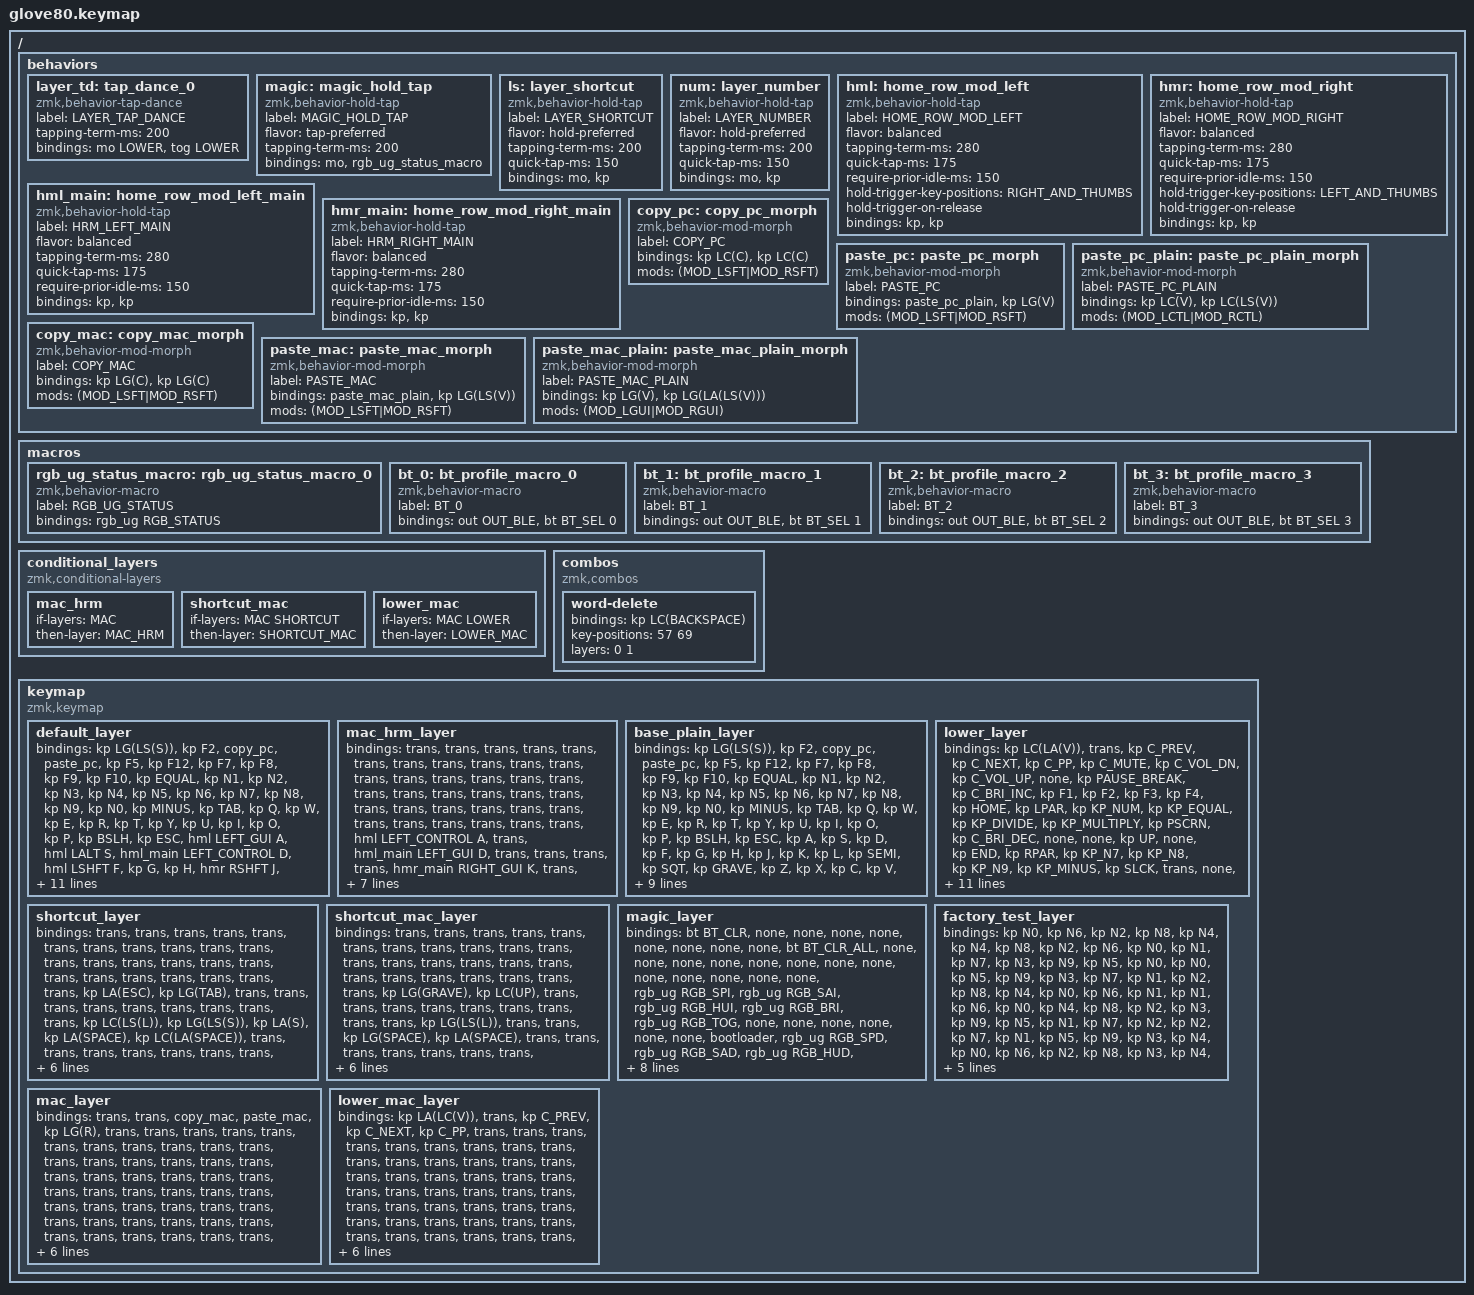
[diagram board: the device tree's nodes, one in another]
/*
 * Copyright (c) 2020 The ZMK Contributors
 *
 * SPDX-License-Identifier: MIT
 */

#include <behaviors.dtsi>
#include <dt-bindings/zmk/bt.h>
#include <dt-bindings/zmk/keys.h>
#include <dt-bindings/zmk/outputs.h>
#include <dt-bindings/zmk/rgb.h>

#define HYPER LC(LS(LG(LALT)))

// ---------------------------------------------------------------------------
// LAYERS
//   0 DEFAULT       base + home row mods. PC/Windows native.
//   1 BASE_PLAIN    same base, home row mods DISABLED (plain letters)
//   2 LOWER         numbers / media / nav  (+ Enter, Backspace, F1-F4)
//   3 SHORTCUT      left-hand shortcut cluster (PC)    -- HOLD left thumb
//   4 SHORTCUT_MAC  left-hand shortcut cluster (Mac)   -- auto when MAC mode on
//   5 MAGIC         BT / RGB / reset + OS & HRM toggles
//   6 FACTORY_TEST  factory test
//   7 MAC           OS flag: while ON, the base layer emits Cmd instead of Ctrl
//   8 LOWER_MAC     Mac variants of the LOWER layer (auto when MAC + LOWER)
//
// TOGGLES (all live on the MAGIC layer, right home row):
//   K = &tog BASE_PLAIN  -> home row mods off / on
//   L = &tog MAC         -> flip PC <-> Mac
//
// NOTE ON OS MODE: ZMK cannot persist layer state across a power cycle, so
// whichever OS is the BASE layer is what you get on boot. The base is PC, so
// Windows works with zero setup; Mac needs MAGIC+L after the board powers on.
//
// IMPORTANT: never use &to on this keymap. ZMK's `to` behavior deactivates
// every layer above its target, which silently wipes the MAC flag (layer 7).
// That is why the HRM toggle and the LOWER lock-exit both use &tog instead.
// ---------------------------------------------------------------------------

#define DEFAULT      0
#define MAC_HRM      1
#define BASE_PLAIN   2
#define LOWER        3
#define SHORTCUT     4
#define SHORTCUT_MAC 5
#define MAGIC        6
#define FACTORY_TEST 7
#define MAC          8
#define LOWER_MAC    9

// Positions of one hand + both thumb clusters, used to make the home row mods
// "positional" (a mod only triggers when combined with a key on the OTHER
// side of the board, so fast same-hand rolls never accidentally hold a mod).
// Right-hand keys + all thumbs  -> allowed triggers for LEFT home row mods

#define RIGHT_AND_THUMBS  5 6 7 8 9 16 17 18 19 20 21 28 29 30 31 32 33 40 41 42 43 44 45 58 59 60 61 62 63 75 76 77 78 79 52 53 54 55 56 57 69 70 71 72 73 74

// Left-hand keys + all thumbs   -> allowed triggers for RIGHT home row mods

#define LEFT_AND_THUMBS   0 1 2 3 4 10 11 12 13 14 15 22 23 24 25 26 27 34 35 36 37 38 39 46 47 48 49 50 51 64 65 66 67 68 52 53 54 55 56 57 69 70 71 72 73 74

/ {
    behaviors {
        // For the "layer" key, it'd nice to be able to use it as either a shift or a toggle.
        // Configure it as a tap dance, so the first tap (or hold) is a &mo and the second tap is a &tog.
        // (&tog, not &to -- see the IMPORTANT note at the top of the file.)

        layer_td: tap_dance_0 {
            compatible = "zmk,behavior-tap-dance";
            label = "LAYER_TAP_DANCE";
            #binding-cells = <0>;
            tapping-term-ms = <200>;
            bindings = <&mo LOWER>, <&tog LOWER>;
        };

        magic: magic_hold_tap {
            compatible = "zmk,behavior-hold-tap";
            label = "MAGIC_HOLD_TAP";
            #binding-cells = <2>;
            flavor = "tap-preferred";
            tapping-term-ms = <200>;
            bindings = <&mo>, <&rgb_ug_status_macro>;
        };

        // Left thumb: tap = Delete, hold = SHORTCUT layer (left-hand shortcuts).

        ls: layer_shortcut {
            compatible = "zmk,behavior-hold-tap";
            label = "LAYER_SHORTCUT";
            #binding-cells = <2>;
            flavor = "hold-preferred";
            tapping-term-ms = <200>;
            quick-tap-ms = <150>;
            bindings = <&mo>, <&kp>;
        };

        // Right thumb: tap = Left Alt, hold = LOWER (number/nav) layer. Lets the
        // whole number layer be reached with the right hand alone. Hold-preferred
        // so numbers register immediately while the thumb is held.

        num: layer_number {
            compatible = "zmk,behavior-hold-tap";
            label = "LAYER_NUMBER";
            #binding-cells = <2>;
            flavor = "hold-preferred";
            tapping-term-ms = <200>;
            quick-tap-ms = <150>;
            bindings = <&mo>, <&kp>;
        };

        // Home row mods, left hand. "balanced" flavor + positional trigger +
        // require-prior-idle gives the "glorious/timeless" feel: taps stay taps
        // while typing, holds only engage when paired with the other hand.

        hml: home_row_mod_left {
            compatible = "zmk,behavior-hold-tap";
            label = "HOME_ROW_MOD_LEFT";
            #binding-cells = <2>;
            flavor = "balanced";
            tapping-term-ms = <280>;
            quick-tap-ms = <175>;
            require-prior-idle-ms = <150>;
            hold-trigger-key-positions = <RIGHT_AND_THUMBS>;
            hold-trigger-on-release;
            bindings = <&kp>, <&kp>;
        };

        // Home row mods, right hand.

        hmr: home_row_mod_right {
            compatible = "zmk,behavior-hold-tap";
            label = "HOME_ROW_MOD_RIGHT";
            #binding-cells = <2>;
            flavor = "balanced";
            tapping-term-ms = <280>;
            quick-tap-ms = <175>;
            require-prior-idle-ms = <150>;
            hold-trigger-key-positions = <LEFT_AND_THUMBS>;
            hold-trigger-on-release;
            bindings = <&kp>, <&kp>;
        };

        // "Main shortcut modifier" home row mods (D and K) -- deliberately NOT
        // positional. They hold Ctrl on PC and Cmd on Mac (MAC_HRM layer swaps
        // them), matching how the thumb Ctrl/Cmd keys swap.
        //
        // Most shortcuts are that modifier + a key on the SAME hand (C/V/X/Z/S/W/T
        // all live under the left hand). The positional variants above cancel the
        // hold in exactly that case, so dropping hold-trigger-key-positions here
        // lets one-handed Ctrl+C / Cmd+C work.
        //
        // require-prior-idle-ms keeps this safe: mid-word a hold is refused
        // outright, so rolls like "de"/"ed" still type letters. If you ever get a
        // stray Ctrl/Cmd while typing, raise require-prior-idle-ms toward 200.

        hml_main: home_row_mod_left_main {
            compatible = "zmk,behavior-hold-tap";
            label = "HRM_LEFT_MAIN";
            #binding-cells = <2>;
            flavor = "balanced";
            tapping-term-ms = <280>;
            quick-tap-ms = <175>;
            require-prior-idle-ms = <150>;
            bindings = <&kp>, <&kp>;
        };

        hmr_main: home_row_mod_right_main {
            compatible = "zmk,behavior-hold-tap";
            label = "HRM_RIGHT_MAIN";
            #binding-cells = <2>;
            flavor = "balanced";
            tapping-term-ms = <280>;
            quick-tap-ms = <175>;
            require-prior-idle-ms = <150>;
            bindings = <&kp>, <&kp>;
        };

        // Copy / paste with Shift masked. Tap = copy / paste. Shift + PASTE
        // opens clipboard history: Win+V on PC, Cmd+Shift+V on Mac.
        // Main modifier + PASTE pastes as plain text: Ctrl on PC, Cmd on Mac
        // (left thumb key next to the letters, or the D/K home-row hold).
        // Holding Shift on the copy key stays a plain copy (Shift is discarded
        // by mod-morph so it never leaks into Ctrl/Cmd+Shift+C).

        copy_pc: copy_pc_morph {
            compatible = "zmk,behavior-mod-morph";
            label = "COPY_PC";
            #binding-cells = <0>;
            bindings = <&kp LC(C)>, <&kp LC(C)>;

            mods = <(MOD_LSFT|MOD_RSFT)>;
        };

        paste_pc: paste_pc_morph {
            compatible = "zmk,behavior-mod-morph";
            label = "PASTE_PC";
            #binding-cells = <0>;
            bindings = <&paste_pc_plain>, <&kp LG(V)>;

            mods = <(MOD_LSFT|MOD_RSFT)>;
        };

        // Ctrl held (masked) -> Ctrl+Shift+V, plain-text paste on Windows.
        paste_pc_plain: paste_pc_plain_morph {
            compatible = "zmk,behavior-mod-morph";
            label = "PASTE_PC_PLAIN";
            #binding-cells = <0>;
            bindings = <&kp LC(V)>, <&kp LC(LS(V))>;

            mods = <(MOD_LCTL|MOD_RCTL)>;
        };

        copy_mac: copy_mac_morph {
            compatible = "zmk,behavior-mod-morph";
            label = "COPY_MAC";
            #binding-cells = <0>;
            bindings = <&kp LG(C)>, <&kp LG(C)>;

            mods = <(MOD_LSFT|MOD_RSFT)>;
        };

        paste_mac: paste_mac_morph {
            compatible = "zmk,behavior-mod-morph";
            label = "PASTE_MAC";
            #binding-cells = <0>;
            bindings = <&paste_mac_plain>, <&kp LG(LS(V))>;

            mods = <(MOD_LSFT|MOD_RSFT)>;
        };

        // Cmd held (masked) -> Option+Shift+Cmd+V, macOS "Paste and Match Style".
        paste_mac_plain: paste_mac_plain_morph {
            compatible = "zmk,behavior-mod-morph";
            label = "PASTE_MAC_PLAIN";
            #binding-cells = <0>;
            bindings = <&kp LG(V)>, <&kp LG(LA(LS(V)))>;

            mods = <(MOD_LGUI|MOD_RGUI)>;
        };
    };

    macros {
        rgb_ug_status_macro: rgb_ug_status_macro_0 {
            label = "RGB_UG_STATUS";
            compatible = "zmk,behavior-macro";
            #binding-cells = <0>;
            bindings = <&rgb_ug RGB_STATUS>;
        };

        bt_0: bt_profile_macro_0 {
            label = "BT_0";
            compatible = "zmk,behavior-macro";
            #binding-cells = <0>;
            bindings = <&out OUT_BLE &bt BT_SEL 0>;
        };

        bt_1: bt_profile_macro_1 {
            label = "BT_1";
            compatible = "zmk,behavior-macro";
            #binding-cells = <0>;
            bindings = <&out OUT_BLE &bt BT_SEL 1>;
        };

        bt_2: bt_profile_macro_2 {
            label = "BT_2";
            compatible = "zmk,behavior-macro";
            #binding-cells = <0>;
            bindings = <&out OUT_BLE &bt BT_SEL 2>;
        };

        bt_3: bt_profile_macro_3 {
            label = "BT_3";
            compatible = "zmk,behavior-macro";
            #binding-cells = <0>;
            bindings = <&out OUT_BLE &bt BT_SEL 3>;
        };
    };

    // While MAC mode (layer 7) AND the SHORTCUT layer (3) are both active, jump
    // to SHORTCUT_MAC (4) so the shortcut cluster emits macOS variants. Keys
    // that are identical on both OSes stay &trans there and fall through to 3.

    conditional_layers {
        compatible = "zmk,conditional-layers";

        // MAC mode swaps the home-row holds back to the Mac layout.
        mac_hrm {
            if-layers = <MAC>;
            then-layer = <MAC_HRM>;
        };

        shortcut_mac {
            if-layers = <MAC SHORTCUT>;
            then-layer = <SHORTCUT_MAC>;
        };

        // While MAC mode (7) AND the LOWER layer (2) are both active, jump to
        // LOWER_MAC (8). Needed because the MAC flag layer sits ABOVE LOWER and
        // would otherwise shadow the media keys, the right-thumb Backspace and
        // the desktop-switch arrows whenever Mac mode is on.

        lower_mac {
            if-layers = <MAC LOWER>;
            then-layer = <LOWER_MAC>;
        };
    };

    combos {
        compatible = "zmk,combos";

        // Delete previous word, via both thumbs. PC uses Ctrl+Backspace.
        //
        // Combos invoke a behavior directly rather than resolving through the
        // keymap, and a combo is live whenever ANY listed layer is active --
        // layer 0 always is -- so this cannot be made to follow the MAC toggle.
        // It is therefore PC-only. For the OS-aware version use the right thumb
        // LOWER key + left thumb Backspace, which is branched properly on the
        // LOWER / LOWER_MAC layers below.

        word-delete {
            bindings = <&kp LC(BACKSPACE)>;
            key-positions = <57 69>;
            layers = <0 1>;
        };
    };

    keymap {
        compatible = "zmk,keymap";

        default_layer {
            // ---------------------------------------------------------------------------------------------------------------------------------
            // | SNIP  |  F2 | COPY | PASTE|  F5  |                                                               |  F12  |  F7   |  F8  |   F9  |  F10 |
            // |  =    |  1  |  2  |  3   |  4   |  5   |                                                 |  6   |   7   |   8   |  9   |   0   |   -  |
            // |  TAB  |  Q  |  W  |  E   |  R   |  T   |                                                 |  Y   |   U   |   I   |  O   |   P   |   \  |
            // |  ESC  | A/W | S/A | D/C  | F/S  |  G   |                                                 |  H   |  J/S  |  K/C  | L/A  |  ;/W  |   '  |
            // |   `   |  Z  |  X  |  C   |  V   |  B   | LCTRL | DEL/SC| LOWER | | LGUI  | RET   | RCTRL |  N   |   M   |   ,   |  .   |   /   | PGUP |
            // | MAGIC | HOME| END | LEFT | RIGHT|      | LSHFT | BSPC  | LALT  | | ALT/L | SPACE | RSHFT |      |  UP   | DOWN  |  [   |   ]   | PGDN |
            //  ( home row mods: A=Win S=Alt D=Ctrl F=Shift  /  J=Shift K=Ctrl L=Alt ;=Win )
            //  ( same positions as the Mac: Mac Cmd -> PC Ctrl, Mac Ctrl -> PC Win, like the thumbs )
            //  ( SNIP = Win+Shift+S, same keycode as Cmd+Shift+S on Mac )
            //  ( COPY=Ctrl+C  PASTE=Ctrl+V (Shift+PASTE=Win+V history, Ctrl+PASTE=plain text)  /  DEL/SC = tap Delete, hold left-hand SHORTCUT layer )
            //  ( Ctrl also lives on the LEFT THUMB so Ctrl+A / Ctrl+C never need a same-hand stretch )

            bindings = <
&kp LG(LS(S))   &kp F2                   &copy_pc     &paste_pc        &kp F5                                                                                                                      &kp F12       &kp F7            &kp F8       &kp F9                       &kp F10
&kp EQUAL       &kp N1                   &kp N2       &kp N3           &kp N4        &kp N5                                                                                                &kp N6  &kp N7        &kp N8            &kp N9       &kp N0                       &kp MINUS
&kp TAB         &kp Q                    &kp W        &kp E            &kp R         &kp T                                                                                                 &kp Y   &kp U         &kp I             &kp O        &kp P                        &kp BSLH
&kp ESC         &hml LEFT_GUI A           &hml LALT S  &hml_main LEFT_CONTROL D  &hml LSHFT F  &kp G                                                                                                 &kp H   &hmr RSHFT J  &hmr_main RIGHT_CONTROL K  &hmr RALT L  &hmr RIGHT_GUI SEMI  &kp SQT
&kp GRAVE       &kp Z                    &kp X        &kp C            &kp V         &kp B   &kp LEFT_CONTROL  &ls SHORTCUT DEL  &layer_td  &kp LEFT_GUI         &kp ENTER  &kp RIGHT_CONTROL      &kp N   &kp M         &kp COMMA         &kp DOT      &kp FSLH                     &kp PG_UP
&magic MAGIC 0  &kp HOME                 &kp END      &kp LEFT         &kp RIGHT             &kp LEFT_SHIFT    &kp BACKSPACE     &kp LALT   &num LOWER LEFT_ALT  &kp SPACE  &kp RIGHT_SHIFT        &kp UP        &kp DOWN          &kp LBKT     &kp RBKT                     &kp PG_DN
            >;
        };

        mac_hrm_layer {
            // Active automatically while MAC is on (conditional layer).
            // Mac home-row holds: A=Ctrl D=Cmd / K=Cmd ;=Ctrl (S/L Alt, F/J Shift unchanged).
            // Sits BELOW BASE_PLAIN, LOWER and SHORTCUT so it never overrides them.

            bindings = <
&trans  &trans  &trans  &trans  &trans  &trans  &trans  &trans  &trans  &trans
&trans  &trans  &trans  &trans  &trans  &trans  &trans  &trans  &trans  &trans  &trans  &trans
&trans  &trans  &trans  &trans  &trans  &trans  &trans  &trans  &trans  &trans  &trans  &trans
&trans  &hml LEFT_CONTROL A  &trans  &hml_main LEFT_GUI D  &trans  &trans  &trans  &trans  &hmr_main RIGHT_GUI K  &trans  &hmr RIGHT_CONTROL SEMI  &trans
&trans  &trans  &trans  &trans  &trans  &trans  &trans  &trans  &trans  &trans  &trans  &trans  &trans  &trans  &trans  &trans  &trans  &trans
&trans  &trans  &trans  &trans  &trans  &trans  &trans  &trans  &trans  &trans  &trans  &trans  &trans  &trans  &trans  &trans
            >;
        };

        base_plain_layer {
            // Identical to DEFAULT but with home row mods disabled (plain A S D F / J K L ;).
            // Reach via MAGIC + K (&tog BASE_PLAIN); press again to turn home row mods back on.
            // Thumb cluster must mirror DEFAULT exactly, or the MAC layer's overrides land
            // on the wrong keys when both are active.

            bindings = <
&kp LG(LS(S))   &kp F2    &copy_pc  &paste_pc  &kp F5                                                                                                                  &kp F12  &kp F7     &kp F8    &kp F9    &kp F10
&kp EQUAL       &kp N1    &kp N2    &kp N3     &kp N4  &kp N5                                                                                                  &kp N6  &kp N7   &kp N8     &kp N9    &kp N0    &kp MINUS
&kp TAB         &kp Q     &kp W     &kp E      &kp R   &kp T                                                                                                   &kp Y   &kp U    &kp I      &kp O     &kp P     &kp BSLH
&kp ESC         &kp A     &kp S     &kp D      &kp F   &kp G                                                                                                   &kp H   &kp J    &kp K      &kp L     &kp SEMI  &kp SQT
&kp GRAVE       &kp Z     &kp X     &kp C      &kp V   &kp B   &kp LEFT_CONTROL  &ls SHORTCUT DEL  &layer_td  &kp LEFT_GUI         &kp ENTER  &kp RIGHT_CONTROL  &kp N   &kp M    &kp COMMA  &kp DOT   &kp FSLH  &kp PG_UP
&magic MAGIC 0  &kp HOME  &kp END   &kp LEFT   &kp RIGHT       &kp LEFT_SHIFT    &kp BACKSPACE     &kp LALT   &num LOWER LEFT_ALT  &kp SPACE  &kp RIGHT_SHIFT           &kp UP   &kp DOWN   &kp LBKT  &kp RBKT  &kp PG_DN
            >;
        };

        lower_layer {
            // Media on top row (left+right). Numpad on right hand. Nav on left.
            // F1-F4 on the left number row, Backspace + Enter on the right thumb.
            // PC native: top-left = Ctrl+Alt+V (Snagit video, mirrors Mac Opt+Ctrl+V), bottom-left
            // arrows = Ctrl+Win+Left/Right (switch virtual desktop), and the left
            // thumb Backspace = Ctrl+Backspace (delete previous word).
            // Exit a locked LOWER with &tog LOWER -- NOT &to, which would wipe MAC mode.

            bindings = <
&kp LC(LA(V))  &trans       &kp C_PREV  &kp C_NEXT        &kp C_PP                                                                                          &kp C_MUTE  &kp C_VOL_DN  &kp C_VOL_UP   &none            &kp PAUSE_BREAK
&kp C_BRI_INC  &kp F1       &kp F2      &kp F3            &kp F4             &kp HOME                                                           &kp LPAR   &kp KP_NUM  &kp KP_EQUAL  &kp KP_DIVIDE  &kp KP_MULTIPLY  &kp PSCRN
&kp C_BRI_DEC  &none        &none       &kp UP            &none              &kp END                                                            &kp RPAR   &kp KP_N7   &kp KP_N8     &kp KP_N9      &kp KP_MINUS     &kp SLCK
&trans         &none        &kp LEFT    &kp DOWN          &kp RIGHT          &kp PG_UP                                                          &kp PRCNT  &kp KP_N4   &kp KP_N5     &kp KP_N6      &kp KP_PLUS      &none
&trans         &kp K_CMENU  &none       &kp F11           &kp F12            &kp PG_DN  &trans  &trans            &tog LOWER  &kp BSPC  &kp RET  &trans     &kp COMMA   &kp KP_N1     &kp KP_N2      &kp KP_N3        &kp BSPC  &trans
&trans         &kp CAPS     &kp INS     &kp LC(LG(LEFT))  &kp LC(LG(RIGHT))             &trans  &kp LC(BACKSPACE)  &trans     &trans    &trans   &trans                 &kp KP_N0   &kp KP_N0     &kp KP_DOT     &kp KP_ENTER     &trans
            >;
        };

        shortcut_layer {
            // Held with the left thumb (Delete key). All actions reachable by the LEFT hand.
            // PC variants (this is the base shortcut layer now):
            //   A = autofill (Ctrl+Shift+L)   S = screenshot (Win+Shift+S)
            //   D = duplicate tab (Alt+S)     F = command palette (Alt+Space)
            //   G = Claude (Ctrl+Alt+Space)
            //   Z = lock (Win+L)  X = clipboard history (Win+V)  C = copy  V = paste
            //   W = cycle windows (Alt+Esc)   E = Task View (Win+Tab)

            bindings = <
&trans  &trans         &trans      &trans      &trans                                                                                    &trans  &trans  &trans  &trans  &trans
&trans  &trans         &trans      &trans      &trans         &trans                                                             &trans  &trans  &trans  &trans  &trans  &trans
&trans  &trans         &kp LA(ESC) &kp LG(TAB) &trans         &trans                                                             &trans  &trans  &trans  &trans  &trans  &trans
&trans  &kp LC(LS(L))  &kp LG(LS(S)) &kp LA(S) &kp LA(SPACE)  &kp LC(LA(SPACE))                                                  &trans  &trans  &trans  &trans  &trans  &trans
&trans  &kp LG(L)      &kp LG(V)   &kp LC(C)   &kp LC(V)      &trans             &trans  &trans  &trans  &trans  &trans  &trans  &trans  &trans  &trans  &trans  &trans  &trans
&trans  &trans         &trans      &trans      &trans                            &trans  &trans  &trans  &trans  &trans  &trans          &trans  &trans  &trans  &trans  &trans
            >;
        };

        shortcut_mac_layer {
            // Mac variants (auto-selected when MAC mode is on). Keys that are identical
            // to PC (screenshot, duplicate tab) stay transparent -> fall to SHORTCUT.
            //   A = autofill (Cmd+Shift+L)    F = Spotlight (Cmd+Space)
            //   G = Claude (Alt+Space)
            //   Z = lock (Ctrl+Cmd+Q)  X = clipboard history (Cmd+Shift+V)
            //   C = copy (Cmd+C)  V = paste (Cmd+V)
            //   W = swap same-app windows (Cmd+`)   E = Mission Control (Ctrl+Up)

            bindings = <
&trans  &trans         &trans         &trans      &trans                                                                                &trans  &trans  &trans  &trans  &trans
&trans  &trans         &trans         &trans      &trans         &trans                                                         &trans  &trans  &trans  &trans  &trans  &trans
&trans  &trans         &kp LG(GRAVE)  &kp LC(UP)  &trans         &trans                                                         &trans  &trans  &trans  &trans  &trans  &trans
&trans  &kp LG(LS(L))  &trans         &trans      &kp LG(SPACE)  &kp LA(SPACE)                                                  &trans  &trans  &trans  &trans  &trans  &trans
&trans  &kp LC(LG(Q))  &kp LG(LS(V))  &kp LG(C)   &kp LG(V)      &trans         &trans  &trans  &trans  &trans  &trans  &trans  &trans  &trans  &trans  &trans  &trans  &trans
&trans  &trans         &trans         &trans      &trans                        &trans  &trans  &trans  &trans  &trans  &trans          &trans  &trans  &trans  &trans  &trans
            >;
        };

        magic_layer {
            // Right home row toggles:
            //   K = &tog BASE_PLAIN  -> home row mods off / on
            //   L = &tog MAC         -> PC <-> Mac
            // Both are &tog, not &to, so flipping one never clears the other.
            // (J used to be "&to 0"; it has been removed because &to wiped MAC mode.)

            bindings = <
&bt BT_CLR   &none            &none            &none            &none                                                                                     &none  &none  &none             &none        &bt BT_CLR_ALL
&none        &none            &none            &none            &none            &none                                                             &none  &none  &none  &none             &none        &none
&none        &rgb_ug RGB_SPI  &rgb_ug RGB_SAI  &rgb_ug RGB_HUI  &rgb_ug RGB_BRI  &rgb_ug RGB_TOG                                                   &none  &none  &none  &none             &none        &none
&bootloader  &rgb_ug RGB_SPD  &rgb_ug RGB_SAD  &rgb_ug RGB_HUD  &rgb_ug RGB_BRD  &rgb_ug RGB_EFF                                                   &none  &none  &tog BASE_PLAIN  &tog MAC  &none        &bootloader
&sys_reset   &none            &none            &none            &none            &none            &bt_2  &bt_3  &none         &none  &none  &none  &none  &none  &none  &none             &none        &sys_reset
&none        &none            &none            &none            &none                             &bt_0  &bt_1  &out OUT_USB  &none  &none  &none         &none  &none  &none             &none        &to FACTORY_TEST
            >;
        };

        factory_test_layer {
            bindings = <
&kp N0  &kp N6  &kp N2  &kp N8  &kp N4                                                                  &kp N4  &kp N8  &kp N2  &kp N6  &kp N0
&kp N1  &kp N7  &kp N3  &kp N9  &kp N5  &kp N0                                                  &kp N0  &kp N5  &kp N9  &kp N3  &kp N7  &kp N1
&kp N2  &kp N8  &kp N4  &kp N0  &kp N6  &kp N1                                                  &kp N1  &kp N6  &kp N0  &kp N4  &kp N8  &kp N2
&kp N3  &kp N9  &kp N5  &kp N1  &kp N7  &kp N2                                                  &kp N2  &kp N7  &kp N1  &kp N5  &kp N9  &kp N3
&kp N4  &kp N0  &kp N6  &kp N2  &kp N8  &kp N3  &kp N4  &kp N5  &kp N6  &kp N6  &kp N5  &kp N4  &kp N3  &kp N8  &kp N2  &kp N6  &kp N0  &kp N4
&kp N5  &kp N1  &kp N7  &kp N3  &kp N9          &kp N7  &kp N8  &kp N9  &kp N9  &kp N8  &kp N7          &kp N9  &kp N3  &kp N7  &kp N1  &kp N5
            >;
        };

        mac_layer {
            // OS flag layer. Toggled on/off with &tog MAC (MAGIC + L). While ON:
            //   - base copy/paste keys emit Cmd (with Shift-masking)
            //   - F5 becomes Cmd+R (Chrome reload on macOS)
            //   - thumb Ctrl <-> Cmd(GUI) are swapped so Cmd is the primary mod
            // Everything else is transparent. Combined with SHORTCUT it activates
            // SHORTCUT_MAC; combined with LOWER it activates LOWER_MAC.
            //
            // Does NOT survive a power cycle: ZMK has no persistent layer state.
            // Re-press MAGIC + L after the board powers on.

            bindings = <
&trans  &trans  &copy_mac  &paste_mac  &kp LG(R)                                                                              &trans  &trans  &trans  &trans  &trans
&trans  &trans  &trans     &trans      &trans  &trans                                                                 &trans  &trans  &trans  &trans  &trans  &trans
&trans  &trans  &trans     &trans      &trans  &trans                                                                 &trans  &trans  &trans  &trans  &trans  &trans
&trans  &trans  &trans     &trans      &trans  &trans                                                                 &trans  &trans  &trans  &trans  &trans  &trans
&trans  &trans  &trans     &trans      &trans  &trans  &kp LEFT_GUI  &trans  &trans  &kp LEFT_CONTROL  &trans  &kp RIGHT_GUI  &trans  &trans  &trans  &trans  &trans  &trans
&trans  &trans  &trans     &trans      &trans          &trans        &trans  &trans  &trans            &trans  &trans         &trans  &trans  &trans  &trans  &trans
            >;
        };

        lower_mac_layer {
            // Mac variants of LOWER (auto when MAC + LOWER are both active).
            //   Top-left -> Option+Ctrl+V (video recording shortcut on the Mac).
            //   F3/F4/F5 -> previous / next track / play-pause. The MAC layer's
            //     Cmd+C / Cmd+V / Cmd+R overlay sits above LOWER and would
            //     otherwise shadow these; LOWER_MAC (8) sits above MAC (7) and
            //     restores them.
            //   Right-thumb Backspace is restored for the same reason (MAC puts
            //     Left Control on that key).
            //   Bottom-left arrows -> Ctrl+Left/Right (switch macOS Space).
            //   Left-thumb Backspace -> Option+Backspace (delete previous word).
            // Everything else is transparent -> falls through to LOWER.

            bindings = <
&kp LA(LC(V))  &trans  &kp C_PREV  &kp C_NEXT    &kp C_PP                                                                                    &trans  &trans  &trans  &trans  &trans
&trans         &trans  &trans      &trans        &trans              &trans                                                          &trans  &trans  &trans  &trans  &trans  &trans
&trans         &trans  &trans      &trans        &trans              &trans                                                          &trans  &trans  &trans  &trans  &trans  &trans
&trans         &trans  &trans      &trans        &trans              &trans                                                          &trans  &trans  &trans  &trans  &trans  &trans
&trans         &trans  &trans      &trans        &trans              &trans  &trans  &trans              &trans  &kp BSPC  &trans  &trans    &trans  &trans  &trans  &trans  &trans  &trans
&trans         &trans  &trans      &kp LC(LEFT)  &kp LC(RIGHT)               &trans  &kp LA(BACKSPACE)   &trans  &trans    &trans  &trans            &trans  &trans  &trans  &trans  &trans
            >;
        };
    };
};
